# A31L21x register map
Vendor: VENDOR ABOV Semiconductor Co., Ltd.; Series: A31L21x; File version: 1.0
CPU: CM0+ r0p1, little endian, no MPU, no FPU, VTOR, 2 interrupt priority bits
Registers are 32-bit, read-write, reset 0x0 unless marked. A register's access mark holds for its fields unless they carry their own. Offsets are from the block's base; [hi:lo] are bit positions.

## RTCC — Real Time Clock and Calendar
Base 0x40005200
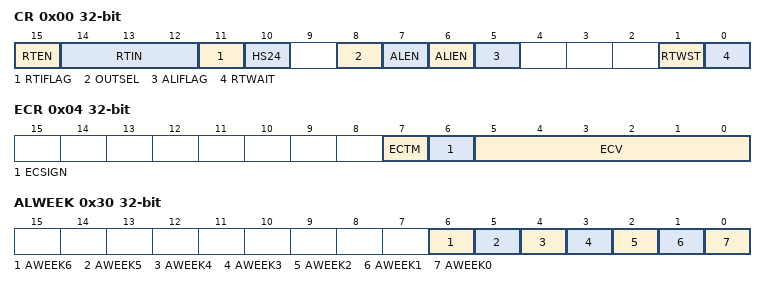
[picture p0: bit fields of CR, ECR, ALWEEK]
0x00 CR — RTCC Control Register
  [15] RTEN — RTCC Enable
  [14:12] RTIN — RTCC Interrupt Interval Selection
  [11] RTIFLAG — RTCC Interval Interrupt Flag
  [10] HS24 — 12/24-hour System Selection
  [8] OUTSEL — RTCOUT Selection
  [7] ALEN — RTCC Alarm Match Operation Enable
  [6] ALIEN — RTCC Alarm Match Interrupt Enable
  [5] ALIFLAG — RTCC Alarm Match Interrupt Flag
  [1] RTWST ro — RTCC Wait Status Flag
  [0] RTWAIT — RTCC Wait Control
0x04 ECR — RTCC Time Error Correcton Register
  [7] ECTM — Time Error Correction Timing Selection
  [6] ECSIGN — Time Error Correction Data Sign
  [5:0] ECV — Time Error Correction Data
0x08 SCNT ro — RTCC Sub-counter Register
  [15:0] RTCNT — RTCC Sub-counter
0x0C SEC — RTCC Second Counter Register
  [6:0] RSEC — RTCC Second Counter
0x10 MIN — RTCC Minute Counter Register
  [6:0] RMIN — RTCC Minute Counter
0x14 HOUR reset 0x12 — RTCC Hour Counter Register
  [6:0] RHOUR — RTCC Hour Counter
0x18 DAY reset 0x1 — RTCC Day Counter Register
  [5:0] RDAY — RTCC Day Counter
0x1C WEEK — RTCC Week Counter Register
  [2:0] RWEEK — RTCC Week Counter
0x20 MONTH reset 0x1 — RTCC Month Counter Register
  [4:0] RMONTH — RTCC Month Counter
0x24 YEAR — RTCC Year Counter Register
  [7:0] RYEAR — RTCC Year Counter
0x28 ALMIN — RTCC Alarm Minute Counter Register
  [6:0] AMIN — RTCC Alarm Minute Counter
0x2C ALHOUR reset 0x12 — RTCC Alarm Hour Counter Register
  [5:0] AHOUR — RTCC Alarm Hour Counter
0x30 ALWEEK — RTCC Alarm Week Counter Register
  [6] AWEEK6 — Saturday Alarm Setting
  [5] AWEEK5 — Friday Alarm Setting
  [4] AWEEK4 — Thursday Alarm Setting
  [3] AWEEK3 — Wednesday Alarm Setting
  [2] AWEEK2 — Tuesday Alarm Setting
  [1] AWEEK1 — Monday Alarm Setting
  [0] AWEEK0 — Sunday Alarm Setting

## TIMER1n — Timer/Counter 1n
Base 0x53000000
Same registers: TIMER10 0x40002100, TIMER11 0x40002180, TIMER12 0x40002200, TIMER13 0x40002280
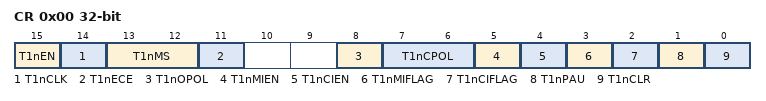
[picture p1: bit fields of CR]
0x00 CR — TIMER1n Control Register
  [15] T1nEN — TIMER1n Operation Enable
  [14] T1nCLK — TIMER1n Clock Selection
  [13:12] T1nMS — TIMER1n Operation Mode Selection
  [11] T1nECE — TIMER1n External Clock Edge Selection
  [8] T1nOPOL — TIMER1n Output Polarity Selection
  [7:6] T1nCPOL — TIMER1n Capture Polarity Selection
  [5] T1nMIEN — TIMER1n Match Interrupt Enable
  [4] T1nCIEN — TIMER1n Capture Interrupt Enable
  [3] T1nMIFLAG — TIMER1n Match Interrupt Flag
  [2] T1nCIFLAG — TIMER1n Capture Interrupt Flag
  [1] T1nPAU — TIMER1n Counter Temporary Pause Control
  [0] T1nCLR — TIMER1n Counter and Prescaler Clear
0x04 ADR reset 0xFFFF — TIMER1n A Data Register
  [15:0] ADATA — TIMER1n A Data
0x08 BDR reset 0xFFFF — TIMER1n B Data Register
  [15:0] BDATA — TIMER1n B Data
0x0C CAPDR ro — TIMER1n Capture Data Register
  [15:0] CAPD — TIMER1n Capture Data
0x10 PREDR reset 0xFFF — TIMER1n Prescaler Data Register
  [11:0] PRED — TIMER1n Prescaler Data
0x14 CNT ro — TIMER1n Counter Register
  [15:0] CNT — TIMER1n Counter

## TIMER5n — Timer/Counter 5n
Base 0x55000000
Same registers: TIMER50 0x40002B00
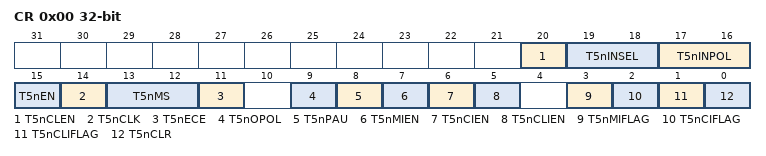
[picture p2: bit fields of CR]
0x00 CR — TIMER5n Control Register
  [20] T5nCLEN — TIMER5n Counter Clear Input Enable
    0=Disable counter clear input; 1=Enable counter clear input at a valid edge by TnINPOL[1:0] bits
  [19:18] T5nINSEL — TIMER5n Capture Signal Selection
    0=ExtClock (Select the external clock.); 1=XSOSC (Select XSOSC.); 2=WDTRC (Select WDTRC.)
  [17:16] T5nINPOL — TIMER5n Capture/'Counter Clear Input' Polarity Selection
    0=FallingEdge (Capture or 'Counter Clear Input' on Falling Edge); 1=RisingEdge (Capture or 'Counter Clear Input' on Rising Edge); 2=BothEdge (Capture or 'Counter Clear Input' on both of Falling and Rising Edge)
  [15] T5nEN — TIMER5n Operation Enable
    0=Disable the timer operation; 1=Enable the timer operation
  [14] T5nCLK — TIMER5n Clock Selection
    0=IntPrescaledClock (Select the internal prescaled clock.); 1=ExtClock (Select the external clock.)
  [13:12] T5nMS — TIMER5n Operation Mode Selection
    0=Interval mode. (T5nOUT: toggle at A-match); 1=Capture mode. (The A-match interrupt can occur); 2=OneShotMode (PPG one-shot mode. (T5nOUT: Programmable pulse output)); 3=PWMMode (PPG repeat mode. (T5nOUT: Programmable pulse output))
  [11] T5nECE — TIMER5n External Clock Edge Selection
    0=FallingEdge (Select falling edge of external clock.); 1=RisingEdge (Select rising edge of external clock.)
  [9] T5nOPOL — T5nOUT Polarity Selection
    0=Start high. (T5nOUT is low level at disable); 1=Start low. (T5nOUT is high level at disable)
  [8] T5nPAU — TIMER5n Counter Temporary Pause Control
    0=Disable (Continue counting); 1=Enable (Temporary pause)
  [7] T5nMIEN — TIMER5n Match Interrupt Enable
    0=Disable the match interrupt; 1=Enable the match interrupt
  [6] T5nCIEN — TIMER5n Capture Interrupt Enable
    0=Disable the capture interrupt; 1=Enable the capture interrupt
  [5] T5nCLIEN — TIMER5n Counter Clear Interrupt Enable
    0=Disable the counter clear input interrupt; 1=Enable the counter clear input interrupt
  [3] T5nMIFLAG — TIMER5n Match Interrupt Flag
    0=No request occurred; 1=Request occurred
  [2] T5nCIFLAG — TIMER5n Capture Interrupt Flag
    0=No request occurred; 1=Request occurred
  [1] T5nCLIFLAG — TIMER5n Counter Clear Input Interrupt Flag
    0=No request occurred; 1=Request occurred
  [0] T5nCLR — TIMER5n Counter and Prescaler Clear
    0=NoEffect; 1=Clear Counter and Prescaler. (Automatically cleared to '0' after operation)
0x04 ADR reset 0xFFFF — TIMER5n A Data Register
  [15:0] ADATA — TIMER5n A Data
0x08 BDR reset 0xFFFF — TIMER5n B Data Register
  [15:0] BDATA — TIMER5n B Data
0x0C CAPDR ro — TIMER5n Capture Data Register
  [15:0] CAPD — TIMER5n Capture Data
0x10 PREDR reset 0xFF — TIMER5n Prescaler Data Register
  [7:0] PRED — TIMER5n Prescaler Data
0x14 CNT ro — TIMER5n Counter Register
  [15:0] CNT — TIMER5n Counter
